# ENCODER0_REG_TOPAZHP_CORE_0 register map
Vendor: Texas Instruments
Peripheral module from a debugger description file (folder J7ES).
Registers are 32-bit, access per field, reset 0x0 unless marked. A register's access mark holds for its fields unless they carry their own. Offsets are as the file gives them; lines under a group give offsets from that group; [hi:lo] are bit positions; {n}, {i} and the like mark numbered series; 'fields as' and 'values as' point back to an identical list; <NAME> marks a mode.

## ENCODER0_REG_TOPAZHP_CORE_0 (part 1 of 2)
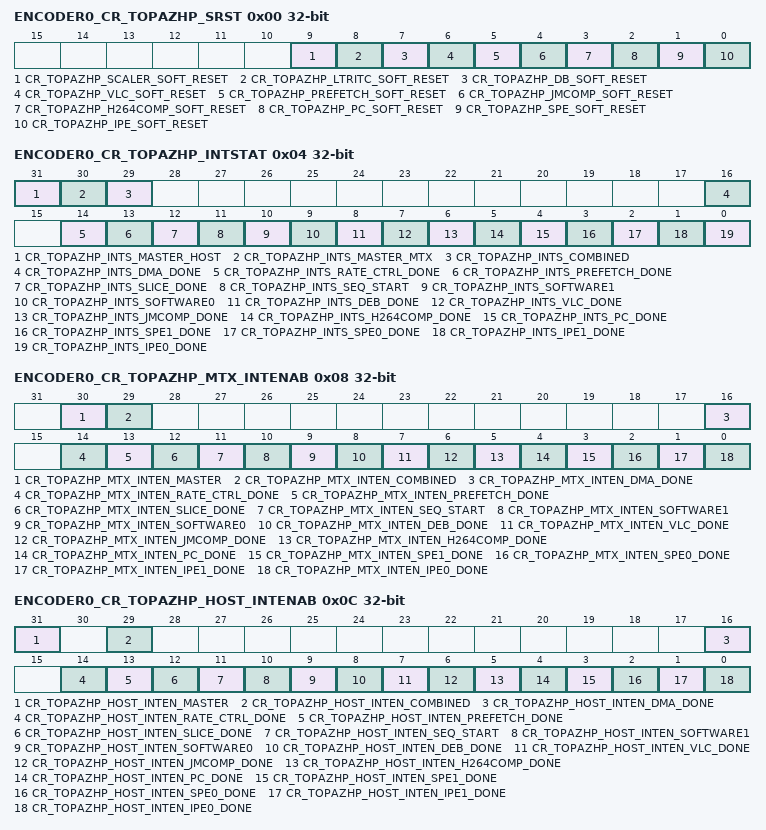
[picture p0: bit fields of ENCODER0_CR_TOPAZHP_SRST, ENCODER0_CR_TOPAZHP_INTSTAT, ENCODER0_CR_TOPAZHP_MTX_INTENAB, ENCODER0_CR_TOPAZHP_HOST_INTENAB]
0x00 ENCODER0_CR_TOPAZHP_SRST
  [9] CR_TOPAZHP_SCALER_SOFT_RESET rw — Input Scaler Software reset:
  [8] CR_TOPAZHP_LTRITC_SOFT_RESET rw — LRITC Software reset:
  [7] CR_TOPAZHP_DB_SOFT_RESET rw — De-blocker Software reset:
  [6] CR_TOPAZHP_VLC_SOFT_RESET rw — VLC Software reset:
  [5] CR_TOPAZHP_PREFETCH_SOFT_RESET rw — Prefetch sequencer Software reset:
  [4] CR_TOPAZHP_JMCOMP_SOFT_RESET rw — JPEG/MPEG Compress Software reset:
  [3] CR_TOPAZHP_H264COMP_SOFT_RESET rw — H264 Compress Software reset:
  [2] CR_TOPAZHP_PC_SOFT_RESET rw — Direct mode/Predictor combiner Software reset:
  [1] CR_TOPAZHP_SPE_SOFT_RESET rw — SPE Software reset [resets both SPE blocks]:
  [0] CR_TOPAZHP_IPE_SOFT_RESET rw — IPE Software reset [resets both IPE blocks]:
0x04 ENCODER0_CR_TOPAZHP_INTSTAT
  [31] CR_TOPAZHP_INTS_MASTER_HOST rw — Indicates that the TopazHP core is activating its host interrupt pin
  [30] CR_TOPAZHP_INTS_MASTER_MTX rw — Indicates that the TopazHP core is activating its mtx interrupt pin
  [29] CR_TOPAZHP_INTS_COMBINED rw — Indicates that Combined interrupt has occurred
  [16] CR_TOPAZHP_INTS_DMA_DONE rw — DMA operation complete
  [14] CR_TOPAZHP_INTS_RATE_CTRL_DONE rw — Indicates the VLC has updated the rate control registers for a basic unit [at start of new basic unit]
  [13] CR_TOPAZHP_INTS_PREFETCH_DONE rw — Indicates the Prefetch Sequencer has completed prefetch stage of current kick [later stages of pipeline may still be processing macroblocks, but new kick could be accepted]
  [12] CR_TOPAZHP_INTS_SLICE_DONE rw — Indicates the Prefetch Sequencer has completed last kick of slice [final stage of pipeline has finished last macroblock in slice, excluding VLC/De-blocker flush]
  [11] CR_TOPAZHP_INTS_SEQ_START rw — Indicates the Prefetch Sequencer has started processing new sequencer kick
  [10] CR_TOPAZHP_INTS_SOFTWARE1 rw — Software interrupt status
  [9] CR_TOPAZHP_INTS_SOFTWARE0 rw — Software interrupt status
  [8] CR_TOPAZHP_INTS_DEB_DONE rw — Indicates that the DEBLOCKER has completed its operation
  [7] CR_TOPAZHP_INTS_VLC_DONE rw — Indicates that VLC has completed its operation
  [6] CR_TOPAZHP_INTS_JMCOMP_DONE rw — Indicates that JMCOMP has completed its operation
  [5] CR_TOPAZHP_INTS_H264COMP_DONE rw — Indicates that H264COMP has completed its operation
  [4] CR_TOPAZHP_INTS_PC_DONE rw — Indicates that Direct mode/Predictor combiner has completed its operation
  [3] CR_TOPAZHP_INTS_SPE1_DONE rw — Indicates that SPE 1 has completed its operation
  [2] CR_TOPAZHP_INTS_SPE0_DONE rw — Indicates that SPE 0 has completed its operation
  [1] CR_TOPAZHP_INTS_IPE1_DONE rw — Indicates that IPE 1 has completed its operation
  [0] CR_TOPAZHP_INTS_IPE0_DONE rw — Indicates that IPE 0 has completed its operation
0x08 ENCODER0_CR_TOPAZHP_MTX_INTENAB — Two interrupt signals are generated by each core. The same interrupt sources are used, but different interrupt masks can be applied. This is mainly intended so that one interrupt is used by MTX, and the other interrupt is used by the Host.
  [30] CR_TOPAZHP_MTX_INTEN_MASTER rw — 0 : Disables all interrupts
  [29] CR_TOPAZHP_MTX_INTEN_COMBINED rw — 0 : Disables the combined interrupt
  [16] CR_TOPAZHP_MTX_INTEN_DMA_DONE rw
  [14] CR_TOPAZHP_MTX_INTEN_RATE_CTRL_DONE rw
  [13] CR_TOPAZHP_MTX_INTEN_PREFETCH_DONE rw
  [12] CR_TOPAZHP_MTX_INTEN_SLICE_DONE rw
  [11] CR_TOPAZHP_MTX_INTEN_SEQ_START rw
  [10] CR_TOPAZHP_MTX_INTEN_SOFTWARE1 rw
  [9] CR_TOPAZHP_MTX_INTEN_SOFTWARE0 rw
  [8] CR_TOPAZHP_MTX_INTEN_DEB_DONE rw
  [7] CR_TOPAZHP_MTX_INTEN_VLC_DONE rw
  [6] CR_TOPAZHP_MTX_INTEN_JMCOMP_DONE rw
  [5] CR_TOPAZHP_MTX_INTEN_H264COMP_DONE rw
  [4] CR_TOPAZHP_MTX_INTEN_PC_DONE rw — 0 : Disables Direct mode/Predictor combiner interrupt
  [3] CR_TOPAZHP_MTX_INTEN_SPE1_DONE rw — 0 : Disables SPE 1 interrupt
  [2] CR_TOPAZHP_MTX_INTEN_SPE0_DONE rw
  [1] CR_TOPAZHP_MTX_INTEN_IPE1_DONE rw
  [0] CR_TOPAZHP_MTX_INTEN_IPE0_DONE rw
0x0C ENCODER0_CR_TOPAZHP_HOST_INTENAB
  [31] CR_TOPAZHP_HOST_INTEN_MASTER rw
  [29] CR_TOPAZHP_HOST_INTEN_COMBINED rw — 0 : Disables the combined interrupt
  [16] CR_TOPAZHP_HOST_INTEN_DMA_DONE rw
  [14] CR_TOPAZHP_HOST_INTEN_RATE_CTRL_DONE rw
  [13] CR_TOPAZHP_HOST_INTEN_PREFETCH_DONE rw
  [12] CR_TOPAZHP_HOST_INTEN_SLICE_DONE rw
  [11] CR_TOPAZHP_HOST_INTEN_SEQ_START rw
  [10] CR_TOPAZHP_HOST_INTEN_SOFTWARE1 rw
  [9] CR_TOPAZHP_HOST_INTEN_SOFTWARE0 rw
  [8] CR_TOPAZHP_HOST_INTEN_DEB_DONE rw
  [7] CR_TOPAZHP_HOST_INTEN_VLC_DONE rw
  [6] CR_TOPAZHP_HOST_INTEN_JMCOMP_DONE rw
  [5] CR_TOPAZHP_HOST_INTEN_H264COMP_DONE rw
  [4] CR_TOPAZHP_HOST_INTEN_PC_DONE rw — 0 : Disables Direct mode/Predictor combiner interrupt
  [3] CR_TOPAZHP_HOST_INTEN_SPE1_DONE rw — 0 : Disables SPE 1 interrupt
  [2] CR_TOPAZHP_HOST_INTEN_SPE0_DONE rw
  [1] CR_TOPAZHP_HOST_INTEN_IPE1_DONE rw
  [0] CR_TOPAZHP_HOST_INTEN_IPE0_DONE rw
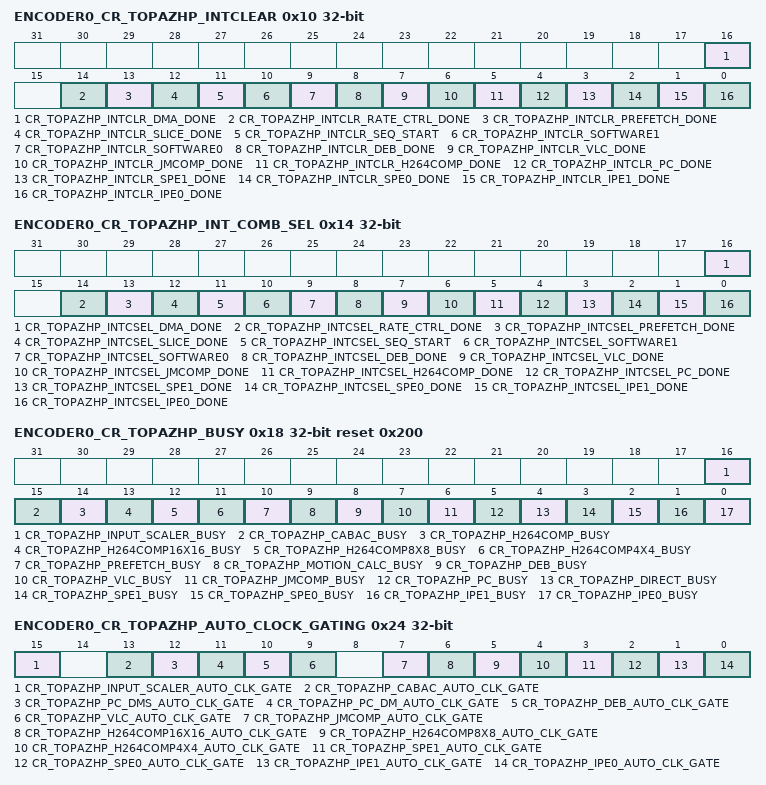
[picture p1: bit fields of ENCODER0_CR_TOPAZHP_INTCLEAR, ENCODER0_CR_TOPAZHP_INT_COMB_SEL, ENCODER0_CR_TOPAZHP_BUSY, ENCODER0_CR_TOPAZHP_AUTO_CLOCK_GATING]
0x10 ENCODER0_CR_TOPAZHP_INTCLEAR
  [16] CR_TOPAZHP_INTCLR_DMA_DONE rw
  [14] CR_TOPAZHP_INTCLR_RATE_CTRL_DONE rw
  [13] CR_TOPAZHP_INTCLR_PREFETCH_DONE rw
  [12] CR_TOPAZHP_INTCLR_SLICE_DONE rw
  [11] CR_TOPAZHP_INTCLR_SEQ_START rw
  [10] CR_TOPAZHP_INTCLR_SOFTWARE1 rw
  [9] CR_TOPAZHP_INTCLR_SOFTWARE0 rw
  [8] CR_TOPAZHP_INTCLR_DEB_DONE rw
  [7] CR_TOPAZHP_INTCLR_VLC_DONE rw
  [6] CR_TOPAZHP_INTCLR_JMCOMP_DONE rw
  [5] CR_TOPAZHP_INTCLR_H264COMP_DONE rw
  [4] CR_TOPAZHP_INTCLR_PC_DONE rw — 0 : No effect
  [3] CR_TOPAZHP_INTCLR_SPE1_DONE rw
  [2] CR_TOPAZHP_INTCLR_SPE0_DONE rw
  [1] CR_TOPAZHP_INTCLR_IPE1_DONE rw
  [0] CR_TOPAZHP_INTCLR_IPE0_DONE rw
0x14 ENCODER0_CR_TOPAZHP_INT_COMB_SEL
  [16] CR_TOPAZHP_INTCSEL_DMA_DONE rw
  [14] CR_TOPAZHP_INTCSEL_RATE_CTRL_DONE rw
  [13] CR_TOPAZHP_INTCSEL_PREFETCH_DONE rw
  [12] CR_TOPAZHP_INTCSEL_SLICE_DONE rw
  [11] CR_TOPAZHP_INTCSEL_SEQ_START rw
  [10] CR_TOPAZHP_INTCSEL_SOFTWARE1 rw
  [9] CR_TOPAZHP_INTCSEL_SOFTWARE0 rw
  [8] CR_TOPAZHP_INTCSEL_DEB_DONE rw
  [7] CR_TOPAZHP_INTCSEL_VLC_DONE rw
  [6] CR_TOPAZHP_INTCSEL_JMCOMP_DONE rw
  [5] CR_TOPAZHP_INTCSEL_H264COMP_DONE rw
  [4] CR_TOPAZHP_INTCSEL_PC_DONE rw — 0 : Do not select
  [3] CR_TOPAZHP_INTCSEL_SPE1_DONE rw
  [2] CR_TOPAZHP_INTCSEL_SPE0_DONE rw
  [1] CR_TOPAZHP_INTCSEL_IPE1_DONE rw
  [0] CR_TOPAZHP_INTCSEL_IPE0_DONE rw
0x18 ENCODER0_CR_TOPAZHP_BUSY ro reset 0x200
  [16] CR_TOPAZHP_INPUT_SCALER_BUSY — 0 : Input scaler is not busy
  [15] CR_TOPAZHP_CABAC_BUSY — 0 : CABAC is not busy
  [14] CR_TOPAZHP_H264COMP_BUSY — 0 : H264COMP is not busy
  [13] CR_TOPAZHP_H264COMP16X16_BUSY — 0 : H264COMP 16x16 is not busy
  [12] CR_TOPAZHP_H264COMP8X8_BUSY — 0 : H264COMP 8x8 is not busy
  [11] CR_TOPAZHP_H264COMP4X4_BUSY — 0 : H264COMP 4x4 is not busy
  [10] CR_TOPAZHP_PREFETCH_BUSY
  [9] CR_TOPAZHP_MOTION_CALC_BUSY
  [8] CR_TOPAZHP_DEB_BUSY
  [7] CR_TOPAZHP_VLC_BUSY
  [6] CR_TOPAZHP_JMCOMP_BUSY
  [5] CR_TOPAZHP_PC_BUSY — 0 : Predictor combiner is not busy
  [4] CR_TOPAZHP_DIRECT_BUSY — 0 : Direct mode is not busy
  [3] CR_TOPAZHP_SPE1_BUSY
  [2] CR_TOPAZHP_SPE0_BUSY
  [1] CR_TOPAZHP_IPE1_BUSY
  [0] CR_TOPAZHP_IPE0_BUSY
0x24 ENCODER0_CR_TOPAZHP_AUTO_CLOCK_GATING
  [15] CR_TOPAZHP_INPUT_SCALER_AUTO_CLK_GATE rw — 0 : Input scaler manual clock gate
  [13] CR_TOPAZHP_CABAC_AUTO_CLK_GATE rw — 0 : CABAC manual clock gate
  [12] CR_TOPAZHP_PC_DMS_AUTO_CLK_GATE rw — 0 : Predictor combiner direct mode manual clock gate
  [11] CR_TOPAZHP_PC_DM_AUTO_CLK_GATE rw — 0 : Predictor combiner decision module manual clock gate
  [10] CR_TOPAZHP_DEB_AUTO_CLK_GATE rw — 0 : De-blocker manual clock gate
  [9] CR_TOPAZHP_VLC_AUTO_CLK_GATE rw — 0 : VLC manual clock gate
  [7] CR_TOPAZHP_JMCOMP_AUTO_CLK_GATE rw — 0 : JMCOMP manual clock gate
  [6] CR_TOPAZHP_H264COMP16X16_AUTO_CLK_GATE rw — 0 : H264COMP 16x16 manual clock gate
  [5] CR_TOPAZHP_H264COMP8X8_AUTO_CLK_GATE rw — 0 : H264COMP 8x8 manual clock gate
  [4] CR_TOPAZHP_H264COMP4X4_AUTO_CLK_GATE rw — 0 : H264COMP 4x4 manual clock gate
  [3] CR_TOPAZHP_SPE1_AUTO_CLK_GATE rw — 0 : SPE 1 manual clock gate
  [2] CR_TOPAZHP_SPE0_AUTO_CLK_GATE rw — 0 : SPE 0 manual clock gate
  [1] CR_TOPAZHP_IPE1_AUTO_CLK_GATE rw — 0 : IPE 1 manual clock gate
  [0] CR_TOPAZHP_IPE0_AUTO_CLK_GATE rw — 0 : IPE 0 manual clock gate
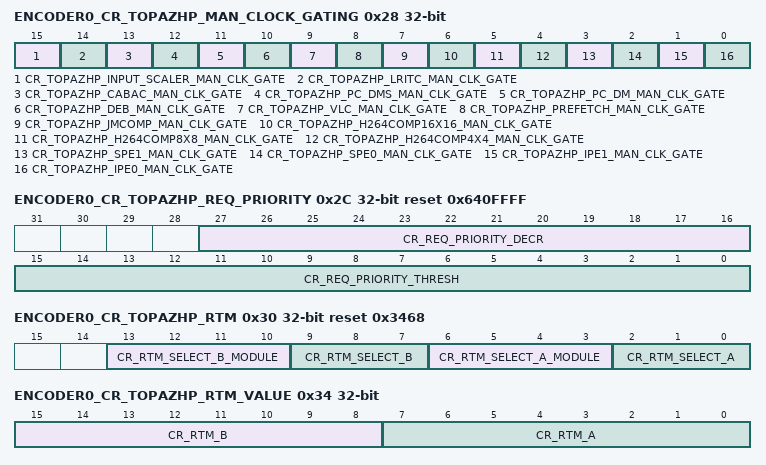
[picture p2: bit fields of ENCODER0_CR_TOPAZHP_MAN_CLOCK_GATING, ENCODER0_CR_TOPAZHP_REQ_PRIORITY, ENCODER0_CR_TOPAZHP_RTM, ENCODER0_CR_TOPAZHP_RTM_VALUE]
0x28 ENCODER0_CR_TOPAZHP_MAN_CLOCK_GATING
  [15] CR_TOPAZHP_INPUT_SCALER_MAN_CLK_GATE rw — 0 : Input scaler clock on
  [14] CR_TOPAZHP_LRITC_MAN_CLK_GATE rw — 0 : LRITC clock on
  [13] CR_TOPAZHP_CABAC_MAN_CLK_GATE rw — 0 : CABAC clock on
  [12] CR_TOPAZHP_PC_DMS_MAN_CLK_GATE rw — 0 : Predictor combiner direct mode clock on
  [11] CR_TOPAZHP_PC_DM_MAN_CLK_GATE rw — 0 : Predictor combiner decision module clock on
  [10] CR_TOPAZHP_DEB_MAN_CLK_GATE rw — 0 : De-blocker clock on
  [9] CR_TOPAZHP_VLC_MAN_CLK_GATE rw — 0 : VLC clock on
  [8] CR_TOPAZHP_PREFETCH_MAN_CLK_GATE rw — 0 : Prefetch sequencer clock on
  [7] CR_TOPAZHP_JMCOMP_MAN_CLK_GATE rw — 0 : JMCOMP clock on
  [6] CR_TOPAZHP_H264COMP16X16_MAN_CLK_GATE rw — 0 : H264COMP 16x16 clock on
  [5] CR_TOPAZHP_H264COMP8X8_MAN_CLK_GATE rw — 0 : H264COMP 8x8 clock on
  [4] CR_TOPAZHP_H264COMP4X4_MAN_CLK_GATE rw — 0 : H264COMP 4x4 clock on
  [3] CR_TOPAZHP_SPE1_MAN_CLK_GATE rw — 0 : SPE 1 clock on
  [2] CR_TOPAZHP_SPE0_MAN_CLK_GATE rw — 0 : SPE 0 clock on
  [1] CR_TOPAZHP_IPE1_MAN_CLK_GATE rw — 0 : IPE 1 clock on
  [0] CR_TOPAZHP_IPE0_MAN_CLK_GATE rw — 0 : IPE 0 clock on
0x2C ENCODER0_CR_TOPAZHP_REQ_PRIORITY reset 0x640FFFF — This register controls the setting of the mem_req_priority output. The request priority output is not aligned to any individual memory transaction but indicates to the bus fabric that the master is not being supplied with enough memory bandwidth to operate at the required performance. A performance counter is incremented every clock cycle that the TopazHP pipeline is active. For every macroblock that is completed (at the VLC stage) the performance counter is decremented by a configurable value (REQ_PRIORITY_DECR). The performance counter is cleared at the end of each slice. The performance counter value is compared to a configurable threshold (REQ_PRIORITY_THRESH) and when the threshold is exceeded the mem_req_priority output for this TopazHP pipe is set. The mem_req_priority output is cleared when the performance counter value falls below the threshold. The external mem_req_priority output to the bus fabric is set when any of the TopazHP pipelines has its individual mem_req_priority output set. The performance counter is clipped to the range {0,1048560} to prevent the counter value from overflowing or underflowing. When the threshold is set to the maximum value (default) the performance counter is disabled (set to zero) and the mem_req_priority output is cleared.
  [27:16] CR_REQ_PRIORITY_DECR rw — Programmable decrement value for performance counter in the range {0,4095}
  [15:0] CR_REQ_PRIORITY_THRESH rw — Programmable theshold with step size 16 giving range {0,1048560}
0x30 ENCODER0_CR_TOPAZHP_RTM reset 0x3468 — Defines the output of ports used for real time monitoring.
  [13:10] CR_RTM_SELECT_B_MODULE rw — Selects the module driving the RTM bus B
  [9:7] CR_RTM_SELECT_B rw — Selects the signals to be monitored from each module
  [6:3] CR_RTM_SELECT_A_MODULE rw — Selects the module driving the RTM bus A
  [2:0] CR_RTM_SELECT_A rw — Selects the signals to be monitored from each module
0x34 ENCODER0_CR_TOPAZHP_RTM_VALUE ro — Provides register read access to the values on the RTM ports.
  [15:8] CR_RTM_B — Value on RTM port B
  [7:0] CR_RTM_A — Value on RTM port A
0x38 ENCODER0_CR_TOPAZHP_MB_PERFORMANCE_RESULT
  [15:0] CR_TOPAZ_MB_PERFORMANCE_RESULT rw — Maximum TopazHP cycle count [cycle counted from VLC start to next VLC start]
0x3C ENCODER0_CR_TOPAZHP_MB_PERFORMANCE_MB_NUMBER
  [15:0] CR_TOPAZ_MB_PERFORMANCE_MB_NUM rw — Macroblock number on which worst case cycle occurred
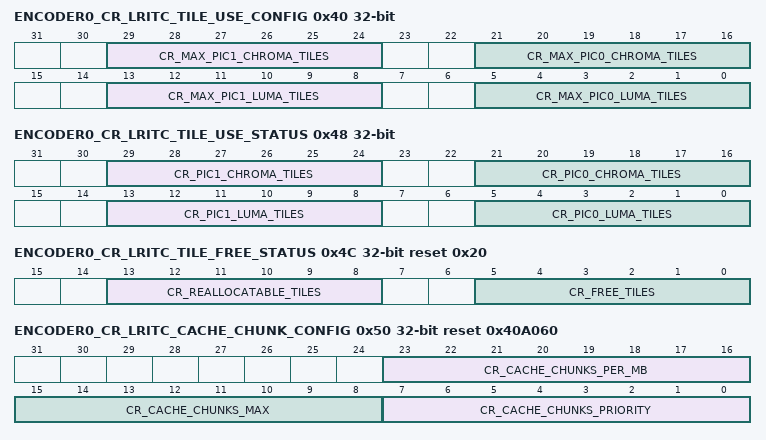
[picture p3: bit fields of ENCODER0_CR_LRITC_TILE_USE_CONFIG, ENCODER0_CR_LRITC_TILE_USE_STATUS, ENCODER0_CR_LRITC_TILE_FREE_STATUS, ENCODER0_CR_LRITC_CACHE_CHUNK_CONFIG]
0x40 ENCODER0_CR_LRITC_TILE_USE_CONFIG — These fields can be used to stop a disproportionate number of tiles being allocated to one plane, which would then starve other planes of tiles. The default configuration for the core is to have 32 tiles available. On an I-frame, the integer motion search can read luma from a reference frame to update the motion search vector field, and therefore all the tiles can be allocated to PIC0_LUMA. In a P-picture with 1 reference frame, more tiles should be allocated to luma, but some tiles should be kept available for chroma, so therefore MAX_PIC0_LUMA may be set to 28, and MAX_PIC0_CHROMA may be set to 8 (where the sum of the thresholds may be greater than the total number of tiles available). For a B-picture, or a P-picture with 2 reference frames, typically PIC0 and PIC1 should be balanced (although more tiles may be alocated to the frame which is further away because the MVs will tend to be larger). It may be desirable to set MAX_PIC0_LUMA and MAX_PIC1_LUMA to 16, and set MAX_PIC0_CHROMA and MAX_PIC1_CHROMA to 8.
  [29:24] CR_MAX_PIC1_CHROMA_TILES rw — Maximum number of tiles allowed to be allocated to reference picture 1 chroma
  [21:16] CR_MAX_PIC0_CHROMA_TILES rw — Maximum number of tiles allowed to be allocated to reference picture 0 chroma
  [13:8] CR_MAX_PIC1_LUMA_TILES rw — Maximum number of tiles allowed to be allocated to reference picture 1 luma
  [5:0] CR_MAX_PIC0_LUMA_TILES rw — Maximum number of tiles allowed to be allocated to reference picture 0 luma
0x48 ENCODER0_CR_LRITC_TILE_USE_STATUS ro
  [29:24] CR_PIC1_CHROMA_TILES — Number of tiles currently allocated to reference picture 1 chroma
  [21:16] CR_PIC0_CHROMA_TILES — Number of tiles currently allocated to reference picture 0 chroma
  [13:8] CR_PIC1_LUMA_TILES — Number of tiles currently allocated to reference picture 1 luma
  [5:0] CR_PIC0_LUMA_TILES — Number of tiles currently allocated to reference picture 0 luma
0x4C ENCODER0_CR_LRITC_TILE_FREE_STATUS ro reset 0x20
  [13:8] CR_REALLOCATABLE_TILES — Number of tiles currently allocated, but which are available for re-allocation
  [5:0] CR_FREE_TILES — Number of tiles currently not allocated
0x50 ENCODER0_CR_LRITC_CACHE_CHUNK_CONFIG reset 0x40A060
  [23:16] CR_CACHE_CHUNKS_PER_MB rw — Average number of cache requests allowed per macroblock
  [15:8] CR_CACHE_CHUNKS_MAX rw — Threshold above which some IPE 16x16 requests are not allowed to request data from host memory
  [7:0] CR_CACHE_CHUNKS_PRIORITY rw — Threshold above which low priority IPE 8x8 requests are not allowed to request data from host memory
0x54 ENCODER0_CR_LRITC_CACHE_CHUNK_STATUS ro
  [7:0] CR_CACHE_REQUEST_COUNT — Count of cache requests issued [increments each time a cache chunk is requested, decremented by CACHE_CHUNKS_PER_MB at the end of each macroblock]
0x58 ENCODER0_CR_LRITC_SIGNATURE_ADDR rw
  [31:0] CR_LRITC_SIGNATURE_ADDR — Signature analysis for address used in read form external host memory
0x5C ENCODER0_CR_LRITC_SIGNATURE_RDATA rw
  [31:0] CR_LRITC_SIGNATURE_RDATA — Signature analysis for data read form external host memory
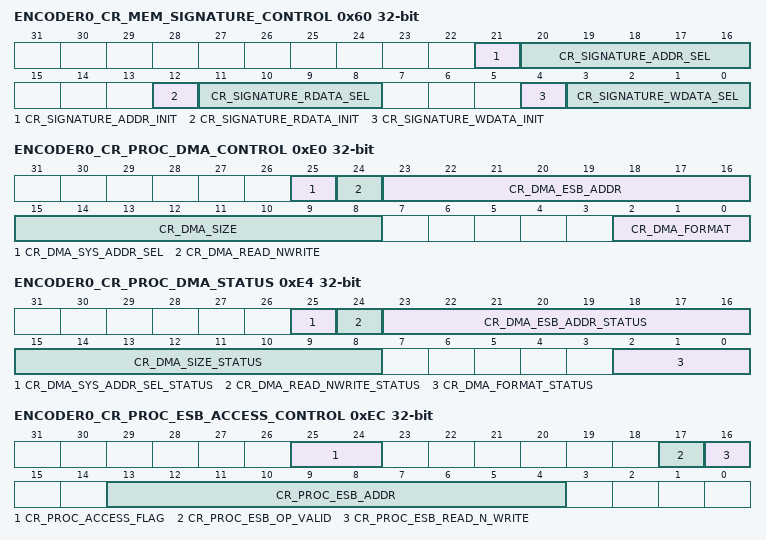
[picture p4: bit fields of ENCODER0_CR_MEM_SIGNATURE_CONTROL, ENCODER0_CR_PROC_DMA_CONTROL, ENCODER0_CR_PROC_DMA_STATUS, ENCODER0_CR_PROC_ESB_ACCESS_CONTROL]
0x60 ENCODER0_CR_MEM_SIGNATURE_CONTROL — Control register which selects which tag Signature analysis should be applied to. Used for test only.
  [21] CR_SIGNATURE_ADDR_INIT rw — 1 : Clear MEM_SIGNATURE_ENC_ADDR CRC
  [20:16] CR_SIGNATURE_ADDR_SEL rw — Selects tag of signature analysis module to read from, signature analysis modules divided memory reads based on tag [the sequence of accesses for different tags is not fixed, so cannot generate single signature for all accesses reliably.
  [12] CR_SIGNATURE_RDATA_INIT rw — 1 : Clear MEM_SIGNATURE_ENC_RDATA CRC
  [11:8] CR_SIGNATURE_RDATA_SEL rw — Selects tag to which signature analysis of data read from external host memory is applied [the sequence of reads for different tags is not fixed, so cannot generate single signature for all reads reliably]
  [4] CR_SIGNATURE_WDATA_INIT rw — 1 : Clear MEM_SIGNATURE_ENC_WDATA CRC
  [3:0] CR_SIGNATURE_WDATA_SEL rw — Selects tag of signature analysis of data written to external host memory to read crc value from [the sequence of writes for different tags is not fixed, so cannot generate single signature for all writes reliably]
0x64 ENCODER0_CR_MEM_SIGNATURE_ENC_WDATA rw — Signature analysis on data written to external memory (for selected tag). Used for test only.
  [31:0] CR_MEM_SIGNATURE_ENC_WDATA — Signature analysis for data written to external host memory for tag selected by SIGNATURE_WDATA_SEL
0x68 ENCODER0_CR_MEM_SIGNATURE_ENC_RDATA rw — Signature analysis on data read from external memory (for selected tag). Used for test only.
  [31:0] CR_MEM_SIGNATURE_ENC_RDATA — Signature analysis for data read from external host memory for tag selected by SIGNATURE_RDATA_SEL
0x6C ENCODER0_CR_MEM_SIGNATURE_ENC_ADDR rw — Signature analysis on address read/written from/to external memory (for selected tag). Used for test only.
  [31:0] CR_MEM_SIGNATURE_ENC_ADDR — Signature analysis for addresses transmitted to external host memory for tag selected by SIGNATURE_ADDR_SEL
0x70 ENCODER0_CR_PREFETCH_LRITC_SIGNATURE rw — Signature analysis on MV candidates sent to LRITC. Used for test only.
  [31:0] CR_PREFETCH_LRITC_SIGNATURE — Signature analysis for MV candidates sent to LRITC.
0xE0 ENCODER0_CR_PROC_DMA_CONTROL — If the DMA engine is currently idle, a write to DMA control register (with DMA_SIZE > 0) will initiate a DMA transfer. If the DMA engine is currently active (DMA_SIZE_STATUS > 0), the write will trigger a new transfer as soon as current transfer completes. At the start of a DMA transfer, the fields from PROC_DMA_CONTROL are transferred into PROC_DMA_STATUS, and DMA_SIZE field is cleared to 0. When a transfer completes, DMA_SIZE_STATUS is cleared to 0.
  [25] CR_DMA_SYS_ADDR_SEL rw — 0 : Use SEQ_CUR_PIC_LUMA_BASE_ADDR and CUR_PIC_LUMA_STRIDE to define address of access in host memory
  [24] CR_DMA_READ_NWRITE rw — 0 : Read from ESB RAM and write to host memory
  [23:16] CR_DMA_ESB_ADDR rw — Address data transferred to/from ESB RAM
  [15:8] CR_DMA_SIZE rw — Number of transfers to make
  [2:0] CR_DMA_FORMAT rw — Format of data in host memory
0xE4 ENCODER0_CR_PROC_DMA_STATUS ro
  [25] CR_DMA_SYS_ADDR_SEL_STATUS — 0 : Use SEQ_CUR_PIC_LUMA_BASE_ADDR and CUR_PIC_LUMA_STRIDE to define address of access in host memory
  [24] CR_DMA_READ_NWRITE_STATUS — 0 : Read from ESB RAM and write to host memory
  [23:16] CR_DMA_ESB_ADDR_STATUS — Address data transferred to/from ESB RAM
  [15:8] CR_DMA_SIZE_STATUS — Number of transfers to make
  [2:0] CR_DMA_FORMAT_STATUS — Format of data in host memory
0xEC ENCODER0_CR_PROC_ESB_ACCESS_CONTROL — The processor/host can use this register to read/write a 128-bit word of ESB memory to/from the ESB_ACCESS_WORD registers. A write to this register can trigger a read or write of ESB RAM (where hardware should stall the write to this register until the corresponding read/write from/to ESB RAM occurs). When using this register to read from the ESB, the firmware must wait for the DMA_SIZE_STATUS field of the PROC_DMA_STATUS register to become zero before the data in the PROC_ESB_ACCESS_WORD registers becomes valid.
  [25:24] CR_PROC_ACCESS_FLAG rw — Software only flags which could be used to control how/what uses ESB_ACCESS registers
  [17] CR_PROC_ESB_OP_VALID rw — Writing 1 triggers read/write operation from/to ESB RAM.
  [16] CR_PROC_ESB_READ_N_WRITE rw — Writing 1 to both PROC_ESB_OP_VALID and PROC_ESB_READ_N_WRITE triggers a read from ESB RAM, where the
  [13:4] CR_PROC_ESB_ADDR rw
0xF0 ENCODER0_CR_PROC_ESB_ACCESS_WORD0 rw
  [31:0] CR_PROC_ESB_WORD0 — The 32 LSBits of 128-bit word read/written to ESB RAM.
0xF4 ENCODER0_CR_PROC_ESB_ACCESS_WORD1 rw
  [31:0] CR_PROC_ESB_WORD1 — Bits 63:32 of 128-bit word read/written to ESB RAM.
0xF8 ENCODER0_CR_PROC_ESB_ACCESS_WORD2 rw
  [31:0] CR_PROC_ESB_WORD2 — Bits 95:64 of 128-bit word read/written to ESB RAM.
0xFC ENCODER0_CR_PROC_ESB_ACCESS_WORD3 rw
  [31:0] CR_PROC_ESB_WORD3 — The 32 MSBits of 128-bit word read/written to ESB RAM.
0x100 ENCODER0_CR_SEQ_CUR_PIC_LUMA_BASE_ADDR
  [31:4] CR_CUR_PIC_LUMA_BASE_ADDR rw — Base address for the Luma plane of the picture to be encoded [always aligned to
0x104 ENCODER0_CR_SEQ_CUR_PIC_CB_BASE_ADDR
  [31:4] CR_CUR_PIC_CB_BASE_ADDR rw — Base address for the Cb plane of the picture to be encoded, or base address of Chroma plane if Chroma is interleaved [always aligned to
0x108 ENCODER0_CR_SEQ_CUR_PIC_CR_BASE_ADDR
  [31:4] CR_CUR_PIC_CR_BASE_ADDR rw — Base address for the Cr plane of the picture to be encoded [not used if Chroma is interleaved] [always aligned to
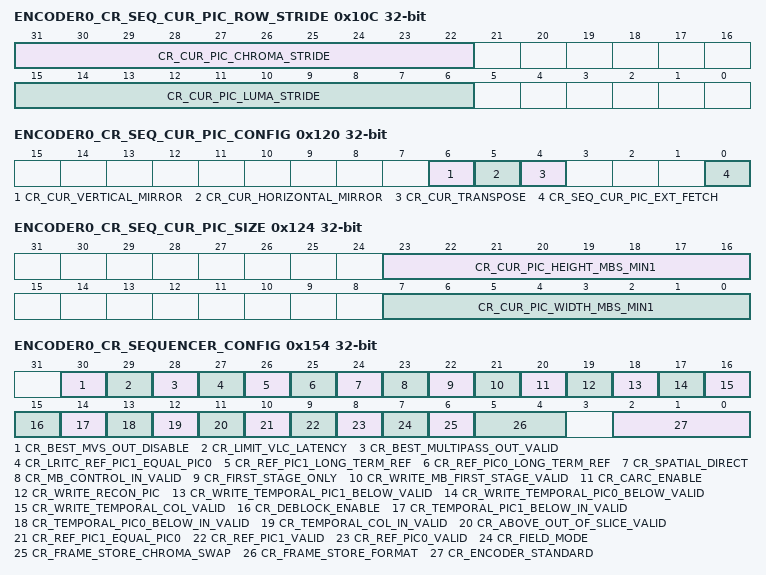
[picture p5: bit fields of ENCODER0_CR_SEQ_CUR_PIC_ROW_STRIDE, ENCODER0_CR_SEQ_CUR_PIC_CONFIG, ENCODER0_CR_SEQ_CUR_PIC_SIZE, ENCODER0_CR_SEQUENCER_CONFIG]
0x10C ENCODER0_CR_SEQ_CUR_PIC_ROW_STRIDE
  [31:22] CR_CUR_PIC_CHROMA_STRIDE rw — Chroma row stride of picture to be encoded [in
  [15:6] CR_CUR_PIC_LUMA_STRIDE rw — Luma row stride of picture to be encoded [in
0x110 ENCODER0_CR_SEQ_REF_PIC0_LUMA_BASE_ADDR
  [31:8] CR_REF_PIC0_LUMA_BASE_ADDR rw — Base address for the Luma plane of reference picture 0 [base address defined in multiple of 256 bytes]
0x114 ENCODER0_CR_SEQ_REF_PIC0_CHROMA_BASE_ADDR
  [31:8] CR_REF_PIC0_CHROMA_BASE_ADDR rw — Base address for the Chroma plane of reference picture 0 [base address defined in multiple of 256 bytes]
0x118 ENCODER0_CR_SEQ_REF_PIC1_LUMA_BASE_ADDR
  [31:8] CR_REF_PIC1_LUMA_BASE_ADDR rw — Base address for the Luma plane of reference picture 1 [base address defined in multiple of 256 bytes]
0x11C ENCODER0_CR_SEQ_REF_PIC1_CHROMA_BASE_ADDR
  [31:8] CR_REF_PIC1_CHROMA_BASE_ADDR rw — Base address for the Chroma plane of reference picture 1 [base address defined in multiple of 256 bytes]
0x120 ENCODER0_CR_SEQ_CUR_PIC_CONFIG
  [6] CR_CUR_VERTICAL_MIRROR rw, [5] CR_CUR_HORIZONTAL_MIRROR rw, [4] CR_CUR_TRANSPOSE rw, [0] CR_SEQ_CUR_PIC_EXT_FETCH rw
0x124 ENCODER0_CR_SEQ_CUR_PIC_SIZE
  [23:16] CR_CUR_PIC_HEIGHT_MBS_MIN1 rw — 1 less than height of picture to be encoded in macroblocks [i.e.
  [7:0] CR_CUR_PIC_WIDTH_MBS_MIN1 rw — 1 less than width of picture to be encoded in macroblocks [i.e.
0x128 ENCODER0_CR_SEQ_RECON_LUMA_BASE_ADDR
  [31:8] CR_RECON_LUMA_BASE_ADDR rw — Base address for the Luma plane of the reconstructed picture generated by the encoding process [where the reconstructed picture could be used as a reference picture when encoding future frames] [base address defined in multiple of 256 bytes]
0x12C ENCODER0_CR_SEQ_RECON_CHROMA_BASE_ADDR
  [31:8] CR_RECON_CHROMA_BASE_ADDR rw — Base address for the Chroma plane of the reconstructed picture generated by the encoding process [where the reconstructed picture could be used as a reference picture when encoding future frames] [base address defined in multiple of 256 bytes]
0x130 ENCODER0_CR_SEQ_ABOVE_PARAM_BASE_ADDR
  [31:6] CR_ABOVE_PARAM_BASE_ADDR rw — Base address for the Above parameters [where parameters for a row of macroblocks are stored to be used in the encoding of the next row] [base address defined in multiple of 64 bytes]
0x134 ENCODER0_CR_SEQ_TEMPORAL_COLOCATED_IN_ADDR
  [31:6] CR_TEMPORAL_COLOC_IN_ADDR rw — Base address for the Temporal co-located motion vector parameters to be used in encode [base address defined in multiple of 64 bytes]
0x138 ENCODER0_CR_SEQ_TEMPORAL_PIC0_MV_IN_ADDR
  [31:6] CR_TEMPORAL_PIC0_IN_ADDR rw — Base address for Temporal motion vectors relative to picture 0 to be used in encode [base address defined in multiple of 64 bytes]
0x13C ENCODER0_CR_SEQ_TEMPORAL_PIC1_MV_IN_ADDR
  [31:6] CR_TEMPORAL_PIC1_IN_ADDR rw — Base address for Temporal motion vectors relative to picture 1 to be used in encode [base address defined in multiple of 64 bytes]
0x140 ENCODER0_CR_SEQ_TEMPORAL_COLOCATED_OUT_ADDR
  [31:6] CR_TEMPORAL_COLOC_OUT_ADDR rw — Base address for the Temporal co-located motion vector parameters written out for use in future frames [base address defined in multiple of 64 bytes]
0x144 ENCODER0_CR_SEQ_TEMPORAL_PIC0_MV_OUT_ADDR
  [31:6] CR_TEMPORAL_PIC0_OUT_ADDR rw — Base address for Temporal motion vectors relative to picture 0 written out for use in future frames [base address defined in multiple of 64 bytes]
0x148 ENCODER0_CR_SEQ_TEMPORAL_PIC1_MV_OUT_ADDR
  [31:6] CR_TEMPORAL_PIC1_OUT_ADDR rw — Base address for Temporal motion vectors relative to picture 1 written out for use in future frames [base address defined in multiple of 64 bytes]
0x14C ENCODER0_CR_SEQ_MB_FIRST_STAGE_OUT_ADDR
  [31:6] CR_MB_FIRST_STAGE_OUT_ADDR rw — Base address to write first stage macroblock data to [base address defined in multiple of 64 bytes]
0x150 ENCODER0_CR_SEQ_MB_CONTROL_IN_ADDR
  [31:6] CR_MB_CONTROL_IN_ADDR rw — Base address to read macroblock control data from [base address defined in multiple of 64 bytes]
0x154 ENCODER0_CR_SEQUENCER_CONFIG
  [30] CR_BEST_MVS_OUT_DISABLE rw — Writing '1' to this bit will disable the best MV output of the multipass structure that is enabled by CR_BEST_MULTIPASS_OUT_VALID
  [29] CR_LIMIT_VLC_LATENCY rw — 0: VLC is up to 2 MBs behind h264comp
  [28] CR_BEST_MULTIPASS_OUT_VALID rw
  [27] CR_LRITC_REF_PIC1_EQUAL_PIC0 rw — This field is ORed with the 'REF_PIC1_EQUAL_PIC0' field, to determine if the LRITC should read two seperate pictures [if both bits are low], or read one reference picture [if either bit is set].
  [26] CR_REF_PIC1_LONG_TERM_REF rw — 0 - Reference Pic 1 is marked as a 'short-term reference' picture
  [25] CR_REF_PIC0_LONG_TERM_REF rw — 0 - Reference Pic 0 is marked as a 'short-term reference' picture
  [24] CR_SPATIAL_DIRECT rw — 0 - Direct vectors are calculated as temporal direct vectors
  [23] CR_MB_CONTROL_IN_VALID rw — 0 - Don't read in per mb control data from host
  [22] CR_FIRST_STAGE_ONLY rw — 0 - Do a full encode
  [21] CR_WRITE_MB_FIRST_STAGE_VALID rw — 0 - Don't write out any macroblock details after IPE stage
  [20] CR_CARC_ENABLE rw — Enables content adaptive rate control - qp is modified on a macroblock by macroblock basis depending on the complexity of the input data.
  [19] CR_WRITE_RECON_PIC rw — 0 : Reconstructed picture not saved [typically only for a B-picture which is not used as reference]
  [18] CR_WRITE_TEMPORAL_PIC1_BELOW_VALID rw — 0 : Don't write temporal below motion vectors for picture 1
  [17] CR_WRITE_TEMPORAL_PIC0_BELOW_VALID rw — 0 : Don't write temporal below motion vectors for picture 0
  [16] CR_WRITE_TEMPORAL_COL_VALID rw — 0 : Don't write temporal colocated motion vectors
  [15] CR_DEBLOCK_ENABLE rw — 0 : Deblocker disabled, pipeline finishes after VLC
  [14] CR_TEMPORAL_PIC1_BELOW_IN_VALID rw — 0 : Don't read temporal below motion vectors for picture 1
  [13] CR_TEMPORAL_PIC0_BELOW_IN_VALID rw — 0 : Don't read temporal below motion vectors for picture 0
  [12] CR_TEMPORAL_COL_IN_VALID rw — 0: Don't read temporal colocated motion vectors
  [11] CR_ABOVE_OUT_OF_SLICE_VALID rw — 0 : Above params from different slice not valid [e.g.
  [10] CR_REF_PIC1_EQUAL_PIC0 rw — 0 : IPE 1 and SPE 1 calculate MV relative to Reference picture 1
  [9] CR_REF_PIC1_VALID rw — If REF_PIC1_EQUAL_PIC
  [8] CR_REF_PIC0_VALID rw — 0 : Reference picture 0 is not valid [typically only on first picture of encode]
  [7] CR_FIELD_MODE rw — 0 : Frame stores point to progressive frame pictures
  [6] CR_FRAME_STORE_CHROMA_SWAP rw — Swap Cb and Cr when reading frame to be encoded
  [5:4] CR_FRAME_STORE_FORMAT rw — Frame store format of frame to be encoded
  [2:0] CR_ENCODER_STANDARD rw — Selects standard to be used for encoding
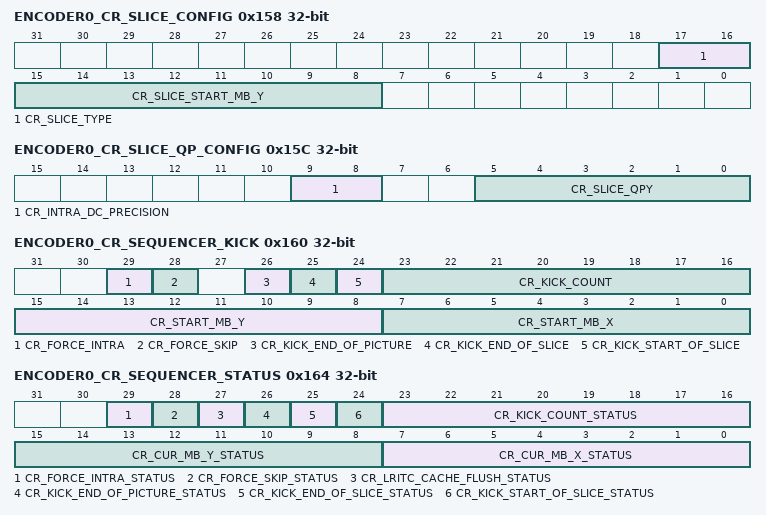
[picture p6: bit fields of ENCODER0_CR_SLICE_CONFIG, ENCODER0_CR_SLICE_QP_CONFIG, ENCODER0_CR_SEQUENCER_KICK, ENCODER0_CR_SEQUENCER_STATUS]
0x158 ENCODER0_CR_SLICE_CONFIG
  [17:16] CR_SLICE_TYPE rw — Slice type
  [15:8] CR_SLICE_START_MB_Y rw — Vertical offset of 1st macroblock of slice [counting from 0]
0x15C ENCODER0_CR_SLICE_QP_CONFIG
  [9:8] CR_INTRA_DC_PRECISION rw — It gives the number of Intra DC precision bits, as shown below:
  [5:0] CR_SLICE_QPY rw — QPy at start of slice, used by VLC to encode current QPy
0x160 ENCODER0_CR_SEQUENCER_KICK — Firmware writes to this register to start processing a number of macroblocks. The register is essentially double buffered, so that when the sequencer is idle, it copies SEQUENCER_KICK register into SEQUENCER_STATUS. While hardware is still active processing macroblocks defined by SEQUENCER_STATUS, firmware can write new value into SEQUENCER_KICK. For JPEG, this register defines number of 8x8 blocks to process, but firmware is responsible for using DMA engine to transfer blocks into ESB RAM before giving kick to this register.
  [29] CR_FORCE_INTRA rw — 1 : Encode all macroblocks in kick as Intra macroblocks
  [28] CR_FORCE_SKIP rw — 1 : Encode all macroblocks in kick as skipped macroblocks
  [26] CR_KICK_END_OF_PICTURE rw — Should only be set to 1 when END_OF_SLICE is also set.
  [25] CR_KICK_END_OF_SLICE rw — 1 : Last macroblock of kick is also last macroblock of a slice
  [24] CR_KICK_START_OF_SLICE rw — 1 : First macroblock of kick is also first macroblock of a slice
  [23:16] CR_KICK_COUNT rw — Number of macroblocks to process in kick [should be greater than 4 to improve memory efficiency, a kick can span more than one row, a value of 0 will do nothing].
  [15:8] CR_START_MB_Y rw — Vertical offset of 1st macroblock in kick to process [ignored for JPEG]
  [7:0] CR_START_MB_X rw — Horizontal offset of 1st macroblock in kick to process.
0x164 ENCODER0_CR_SEQUENCER_STATUS ro — If LRITC_CACHE_FLUSH == 0, when KICK_COUNT_STATUS is 0, and KICK_COUNT in SEQUENCER_KICK register is non-zero, the contents of SEQUENCER_KICK are copied into SEQUENCER_STATUS, and KICK_COUNT is cleared to 0. If LRITC_CACHE_FLUSH == 1, hardware waits for previous kick to completely finish, since LRITC_CACHE_FLUSH also resets region pointers, which would corrupt anything currently being processed.
  [29] CR_FORCE_INTRA_STATUS
  [28] CR_FORCE_SKIP_STATUS
  [27] CR_LRITC_CACHE_FLUSH_STATUS
  [26] CR_KICK_END_OF_PICTURE_STATUS — Last macroblock of kick is also last macroblock of a picture
  [25] CR_KICK_END_OF_SLICE_STATUS — Last macroblock of kick is also last macroblock of a slice
  [24] CR_KICK_START_OF_SLICE_STATUS — First macroblock of kick is also first macroblock of a slice
  [23:16] CR_KICK_COUNT_STATUS — Number of macroblocks left to process in current kick [will automatically decrement each time motion vector calculation state machine finishes calculating vectors for a macroblock].
  [15:8] CR_CUR_MB_Y_STATUS — Vertical offset of current macroblock being processed at prefetch stage [updates at same time KICK_COUNT_STATUS decrements].
  [7:0] CR_CUR_MB_X_STATUS — Horizontal offset of current macroblock being processed at prefetch stage [updates at same time KICK_COUNT_STATUS decrements].
0x168 ENCODER0_CR_SEQ_BEST_MULTIPASS_OUT_ADDR
  [31:6] CR_BEST_MULTIPASS_OUT_ADDR rw — Base address to write best multipass structure to [base address defined in multiple of 64 bytes]
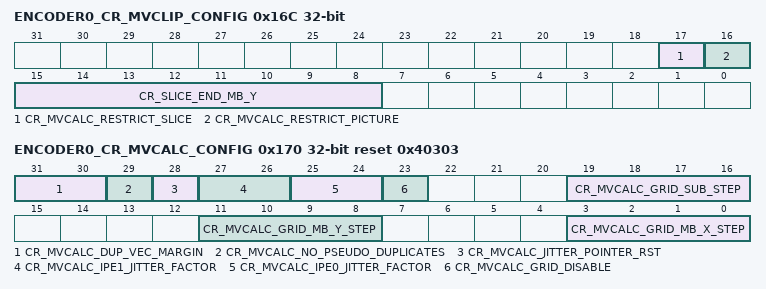
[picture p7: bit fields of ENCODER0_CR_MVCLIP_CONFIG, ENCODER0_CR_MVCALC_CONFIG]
0x16C ENCODER0_CR_MVCLIP_CONFIG
  [17] CR_MVCALC_RESTRICT_SLICE rw
  [16] CR_MVCALC_RESTRICT_PICTURE rw
  [15:8] CR_SLICE_END_MB_Y rw — Vertical offset of last row of macroblocks in slice, used in constraining motion vectors to current slice area
0x170 ENCODER0_CR_MVCALC_CONFIG reset 0x40303
  [31:30] CR_MVCALC_DUP_VEC_MARGIN rw — Extra margin around IPE candidate vectors used to detect duplicate vector.
  [29] CR_MVCALC_NO_PSEUDO_DUPLICATES rw — Writing '1' to this bit will prevent pseudo MVs being sent to LRITC when both the candidate MV and its jittered value are duplicates
  [28] CR_MVCALC_JITTER_POINTER_RST rw — Writing '1' to this bit resets the jitter table pointers
  [27:26] CR_MVCALC_IPE1_JITTER_FACTOR rw — Jitter factor for IPE1, add one and multiply fixed jitter table, unsigned
  [25:24] CR_MVCALC_IPE0_JITTER_FACTOR rw — Jitter factor for IPE0, add one and multiply fixed jitter table, unsigned
  [23] CR_MVCALC_GRID_DISABLE rw — When set, the grid search candidates are not used
  [19:16] CR_MVCALC_GRID_SUB_STEP rw — Step size used if there are multiple pseudo-grid search candidates per macroblock
  [11:8] CR_MVCALC_GRID_MB_Y_STEP rw — Vertical step size used in pseudo-grid search algorithm
  [3:0] CR_MVCALC_GRID_MB_X_STEP rw — Horizontal step size used in pseudo-grid search algorithm
